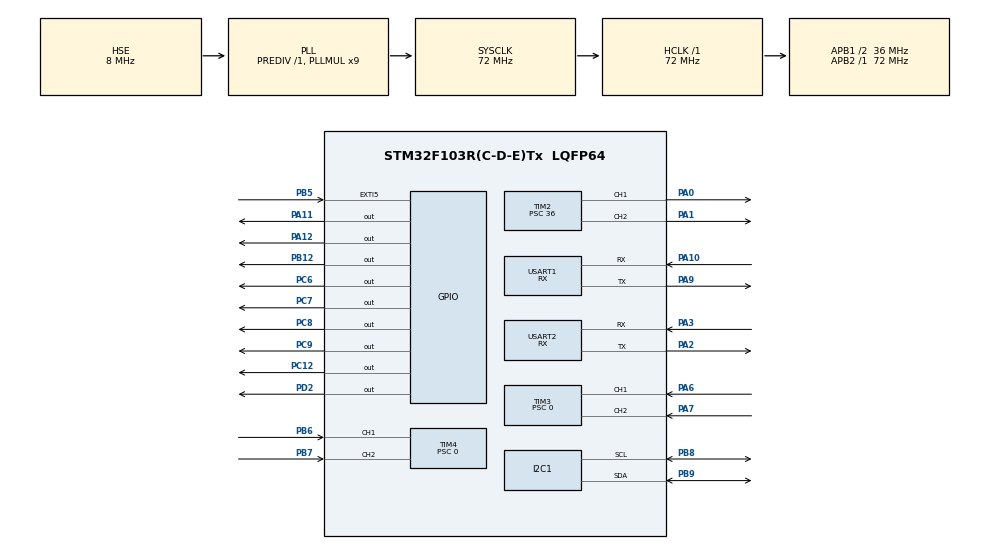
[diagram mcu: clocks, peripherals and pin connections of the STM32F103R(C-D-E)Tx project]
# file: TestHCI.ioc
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Dma.I2C1_RX.2.Direction=DMA_PERIPH_TO_MEMORY
Dma.I2C1_RX.2.Instance=DMA1_Channel7
Dma.I2C1_RX.2.MemDataAlignment=DMA_MDATAALIGN_BYTE
Dma.I2C1_RX.2.MemInc=DMA_MINC_ENABLE
Dma.I2C1_RX.2.Mode=DMA_CIRCULAR
Dma.I2C1_RX.2.PeriphDataAlignment=DMA_PDATAALIGN_BYTE
Dma.I2C1_RX.2.PeriphInc=DMA_PINC_DISABLE
Dma.I2C1_RX.2.Priority=DMA_PRIORITY_MEDIUM
Dma.Request0=USART1_RX
Dma.Request1=USART2_RX
Dma.Request2=I2C1_RX
Dma.USART1_RX.0.Direction=DMA_PERIPH_TO_MEMORY
Dma.USART1_RX.0.Instance=DMA1_Channel5
Dma.USART1_RX.0.MemDataAlignment=DMA_MDATAALIGN_BYTE
Dma.USART1_RX.0.MemInc=DMA_MINC_ENABLE
Dma.USART1_RX.0.Mode=DMA_CIRCULAR
Dma.USART1_RX.0.PeriphDataAlignment=DMA_PDATAALIGN_BYTE
Dma.USART1_RX.0.PeriphInc=DMA_PINC_DISABLE
Dma.USART1_RX.0.Priority=DMA_PRIORITY_HIGH
Dma.USART2_RX.1.Direction=DMA_PERIPH_TO_MEMORY
Dma.USART2_RX.1.Instance=DMA1_Channel6
Dma.USART2_RX.1.MemDataAlignment=DMA_MDATAALIGN_BYTE
Dma.USART2_RX.1.MemInc=DMA_MINC_ENABLE
Dma.USART2_RX.1.Mode=DMA_CIRCULAR
Dma.USART2_RX.1.PeriphDataAlignment=DMA_PDATAALIGN_BYTE
Dma.USART2_RX.1.PeriphInc=DMA_PINC_DISABLE
Dma.USART2_RX.1.Priority=DMA_PRIORITY_HIGH
Mcu.Family=STM32F1
Mcu.Name=STM32F103R(C-D-E)Tx
Mcu.Package=LQFP64
NVIC.DMA1_Channel5_IRQn=true\:1\:0\:true\:false\:true
NVIC.DMA1_Channel6_IRQn=true\:1\:0\:true\:false\:true
NVIC.DMA1_Channel7_IRQn=true\:1\:1\:true\:false\:true
NVIC.PriorityGroup=NVIC_PRIORITYGROUP_2
PA0-WKUP.GPIO_Speed=GPIO_SPEED_FREQ_HIGH
PA0-WKUP.Signal=S_TIM2_CH1_ETR
PA1.GPIO_Speed=GPIO_SPEED_FREQ_HIGH
PA1.Signal=S_TIM2_CH2
PA10.Mode=Asynchronous
PA10.Signal=USART1_RX
PA11.GPIO_Speed=GPIO_SPEED_FREQ_HIGH
PA11.Signal=GPIO_Output
PA12.GPIO_Speed=GPIO_SPEED_FREQ_HIGH
PA12.Signal=GPIO_Output
PA13.Mode=Serial_Wire
PA13.Signal=SYS_JTMS-SWDIO
PA14.Mode=Serial_Wire
PA14.Signal=SYS_JTCK-SWCLK
PA2.Mode=Asynchronous
PA2.Signal=USART2_TX
PA3.Mode=Asynchronous
PA3.Signal=USART2_RX
PA6.Signal=S_TIM3_CH1
PA7.Signal=S_TIM3_CH2
PA9.Mode=Asynchronous
PA9.Signal=USART1_TX
PB12.GPIO_Speed=GPIO_SPEED_FREQ_HIGH
PB12.Signal=GPIO_Output
PB5.Signal=GPXTI5
PB6.Signal=S_TIM4_CH1
PB7.Signal=S_TIM4_CH2
PB8.Mode=I2C
PB8.Signal=I2C1_SCL
PB9.Mode=I2C
PB9.Signal=I2C1_SDA
PC12.GPIO_Speed=GPIO_SPEED_FREQ_HIGH
PC12.Signal=GPIO_Output
PC6.GPIO_Speed=GPIO_SPEED_FREQ_HIGH
PC6.Signal=GPIO_Output
PC7.GPIO_Speed=GPIO_SPEED_FREQ_HIGH
PC7.Signal=GPIO_Output
PC8.GPIO_Speed=GPIO_SPEED_FREQ_HIGH
PC8.Signal=GPIO_Output
PC9.GPIO_Speed=GPIO_SPEED_FREQ_HIGH
PC9.Signal=GPIO_Output
PD0-OSC_IN.Mode=HSE-External-Oscillator
PD0-OSC_IN.Signal=RCC_OSC_IN
PD1-OSC_OUT.Mode=HSE-External-Oscillator
PD1-OSC_OUT.Signal=RCC_OSC_OUT
PD2.GPIO_Speed=GPIO_SPEED_FREQ_HIGH
PD2.Signal=GPIO_Output
ProjectManager.HeapSize=0x200
ProjectManager.StackSize=0x400
ProjectManager.TargetToolchain=MDK-ARM V5
RCC.AHBFreq_Value=72000000
RCC.APB1CLKDivider=RCC_HCLK_DIV2
RCC.APB1Freq_Value=36000000
RCC.APB1TimFreq_Value=72000000
RCC.APB2Freq_Value=72000000
RCC.APB2TimFreq_Value=72000000
RCC.HCLKFreq_Value=72000000
RCC.HSIState=RCC_HSI_ON
RCC.PLLMUL=RCC_PLL_MUL9
RCC.PLLSourceVirtual=RCC_PLLSOURCE_HSE
RCC.SYSCLKFreq_VALUE=72000000
RCC.SYSCLKSource=RCC_SYSCLKSOURCE_PLLCLK
RCC.USBFreq_Value=72000000
SH.S_TIM2_CH1_ETR.0=TIM2_CH1,PWM Generation1 CH1
SH.S_TIM2_CH2.0=TIM2_CH2,PWM Generation2 CH2
SH.S_TIM3_CH1.0=TIM3_CH1,Encoder_Interface
SH.S_TIM3_CH2.0=TIM3_CH2,Encoder_Interface
SH.S_TIM4_CH1.0=TIM4_CH1,Encoder_Interface
SH.S_TIM4_CH2.0=TIM4_CH2,Encoder_Interface
TIM2.Channel-PWM\ Generation2\ CH2=TIM_CHANNEL_2
TIM2.Period=1560
TIM2.Prescaler=36
TIM2.Pulse-PWM\ Generation1\ CH1=0
TIM2.Pulse-PWM\ Generation2\ CH2=0
TIM3.CounterMode=TIM_COUNTERMODE_UP
TIM3.EncoderMode=TIM_ENCODERMODE_TI12
TIM3.IC1Filter=15
TIM3.IC1Polarity=TIM_ICPOLARITY_BOTHEDGE
TIM3.IC2Filter=15
TIM3.IC2Polarity=TIM_ICPOLARITY_BOTHEDGE
TIM3.Period=10000
TIM3.Prescaler=0
TIM4.EncoderMode=TIM_ENCODERMODE_TI12
TIM4.IC1Filter=15
TIM4.IC1Polarity=TIM_ICPOLARITY_BOTHEDGE
TIM4.IC2Filter=15
TIM4.IC2Polarity=TIM_ICPOLARITY_BOTHEDGE
TIM4.Period=10000
TIM4.Prescaler=0
USART1.Mode=MODE_RX
USART2.Mode=MODE_RX
board=TestHCI

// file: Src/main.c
/**
  ******************************************************************************
  * File Name          : main.c
  * Description        : Main program body
  ******************************************************************************
  *
  * COPYRIGHT(c) 2016 STMicroelectronics
  *
  * Redistribution and use in source and binary forms, with or without modification,
  * are permitted provided that the following conditions are met:
  *   1. Redistributions of source code must retain the above copyright notice,
  *      this list of conditions and the following disclaimer.
  *   2. Redistributions in binary form must reproduce the above copyright notice,
  *      this list of conditions and the following disclaimer in the documentation
  *      and/or other materials provided with the distribution.
  *   3. Neither the name of STMicroelectronics nor the names of its contributors
  *      may be used to endorse or promote products derived from this software
  *      without specific prior written permission.
  *
  * THIS SOFTWARE IS PROVIDED BY THE COPYRIGHT HOLDERS AND CONTRIBUTORS "AS IS"
  * AND ANY EXPRESS OR IMPLIED WARRANTIES, INCLUDING, BUT NOT LIMITED TO, THE
  * IMPLIED WARRANTIES OF MERCHANTABILITY AND FITNESS FOR A PARTICULAR PURPOSE ARE
  * DISCLAIMED. IN NO EVENT SHALL THE COPYRIGHT HOLDER OR CONTRIBUTORS BE LIABLE
  * FOR ANY DIRECT, INDIRECT, INCIDENTAL, SPECIAL, EXEMPLARY, OR CONSEQUENTIAL
  * DAMAGES (INCLUDING, BUT NOT LIMITED TO, PROCUREMENT OF SUBSTITUTE GOODS OR
  * SERVICES; LOSS OF USE, DATA, OR PROFITS; OR BUSINESS INTERRUPTION) HOWEVER
  * CAUSED AND ON ANY THEORY OF LIABILITY, WHETHER IN CONTRACT, STRICT LIABILITY,
  * OR TORT (INCLUDING NEGLIGENCE OR OTHERWISE) ARISING IN ANY WAY OUT OF THE USE
  * OF THIS SOFTWARE, EVEN IF ADVISED OF THE POSSIBILITY OF SUCH DAMAGE.
  *
  ******************************************************************************
  */
#include "main.h"
#include "stm32f1xx_hal.h"
#include "dma.h"
#include "i2c.h"
#include "tim.h"
#include "usart.h"
#include "gpio.h"

/* USER CODE BEGIN Includes */
#include "delay.h"
#include "parseJY.h"
#include "motor_cont.h"
#include "imuPID.h"
#include "mpr121.h"

/* USER CODE END Includes */

/* USER CODE BEGIN PV */
/* Private variables ---------------------------------------------------------*/
//static uint8_t uwbData[10];

/* USER CODE END PV */

void SystemClock_Config(void);
void Error_Handler(void);

/* USER CODE BEGIN PFP */
/* Private function prototypes -----------------------------------------------*/

/* USER CODE END PFP */

int main(void)
{

  /* USER CODE BEGIN 1 */
//	static uint8_t cntLength = 0;

  /* USER CODE END 1 */

  /* MCU Configuration----------------------------------------------------------*/

  /* Reset of all peripherals, Initializes the Flash interface and the Systick. */
  HAL_Init();

  /* Configure the system clock */
  SystemClock_Config();

  /* Initialize all configured peripherals */
  MX_GPIO_Init();
  MX_DMA_Init();
  MX_TIM2_Init();
  MX_TIM3_Init();
  MX_TIM4_Init();
  MX_USART1_UART_Init();
  MX_USART2_UART_Init();
  MX_I2C1_Init();

  /* USER CODE BEGIN 2 */
	initJY();

	HAL_TIM_PWM_Start(&htim2, TIM_CHANNEL_1);
	HAL_TIM_PWM_Start(&htim2, TIM_CHANNEL_2);

	HAL_TIM_Encoder_Start(&htim3, TIM_CHANNEL_1);
	HAL_TIM_Encoder_Start(&htim3, TIM_CHANNEL_2);

	HAL_TIM_Encoder_Start(&htim4, TIM_CHANNEL_1);
	HAL_TIM_Encoder_Start(&htim4, TIM_CHANNEL_2);

	mpr121_Init();

//	DelayMS(10000);
	HAL_GPIO_WritePin(GPIOD, GPIO_PIN_2, GPIO_PIN_SET); //Debug led.

//	car_Awake();
//	car_FastDecay();
//
////	for(cntLength = 0; cntLength < 6; cntLength++)
////	{
//		car_GoLength(1560 * 3.11 * 6);
//		while(ifTurnStable());
////	}
//
//	car_Turn(90.0);
//	while(ifTurnToStable());
//
////	for(cntLength = 0; cntLength < 9; cntLength++)
////	{
//		car_GoLength(1560 * 3.11 * 9);
//		while(ifTurnStable());
////	}
//
//	car_Sleep();
//	DelayMS(5000);
//	car_Awake();
//
//	car_Turn(180.0);
//	while(ifTurnToStable());
//
////	for(cntLength = 0; cntLength < 8; cntLength++)
////	{
//		car_GoLength(1560 * 3.11 * 8);
//		while(ifTurnStable());
////	}
//
//	car_Turn(-95.0);
//	while(ifTurnToStable());
//
////	for(cntLength = 0; cntLength < 6; cntLength++)
////	{
//		car_GoLength(1560 * 3.11 * 3.8);
//		while(ifTurnStable());
////	}
//
//	car_Sleep();

  /* USER CODE END 2 */

  /* Infinite loop */
  while (1)
  {

  }

}

/** System Clock Configuration
*/
void SystemClock_Config(void)
{

  RCC_OscInitTypeDef RCC_OscInitStruct;
  RCC_ClkInitTypeDef RCC_ClkInitStruct;

    /**Initializes the CPU, AHB and APB busses clocks
    */
  RCC_OscInitStruct.OscillatorType = RCC_OSCILLATORTYPE_HSE;
  RCC_OscInitStruct.HSEState = RCC_HSE_ON;
  RCC_OscInitStruct.HSEPredivValue = RCC_HSE_PREDIV_DIV1;
  RCC_OscInitStruct.HSIState = RCC_HSI_ON;
  RCC_OscInitStruct.PLL.PLLState = RCC_PLL_ON;
  RCC_OscInitStruct.PLL.PLLSource = RCC_PLLSOURCE_HSE;
  RCC_OscInitStruct.PLL.PLLMUL = RCC_PLL_MUL9;
  if (HAL_RCC_OscConfig(&RCC_OscInitStruct) != HAL_OK)
  {
    Error_Handler();
  }

    /**Initializes the CPU, AHB and APB busses clocks
    */
  RCC_ClkInitStruct.ClockType = RCC_CLOCKTYPE_HCLK|RCC_CLOCKTYPE_SYSCLK
                              |RCC_CLOCKTYPE_PCLK1|RCC_CLOCKTYPE_PCLK2;
  RCC_ClkInitStruct.SYSCLKSource = RCC_SYSCLKSOURCE_PLLCLK;
  RCC_ClkInitStruct.AHBCLKDivider = RCC_SYSCLK_DIV1;
  RCC_ClkInitStruct.APB1CLKDivider = RCC_HCLK_DIV2;
  RCC_ClkInitStruct.APB2CLKDivider = RCC_HCLK_DIV1;

  if (HAL_RCC_ClockConfig(&RCC_ClkInitStruct, FLASH_LATENCY_2) != HAL_OK)
  {
    Error_Handler();
  }

    /**Configure the Systick interrupt time
    */
  HAL_SYSTICK_Config(HAL_RCC_GetHCLKFreq()/1000);

    /**Configure the Systick
    */
  HAL_SYSTICK_CLKSourceConfig(SYSTICK_CLKSOURCE_HCLK);

  /* SysTick_IRQn interrupt configuration */
  HAL_NVIC_SetPriority(SysTick_IRQn, 0, 1);
}

void Error_Handler(void)
{
  while(1)
  {
  }
}

/************************ (C) COPYRIGHT STMicroelectronics *****END OF FILE****/
